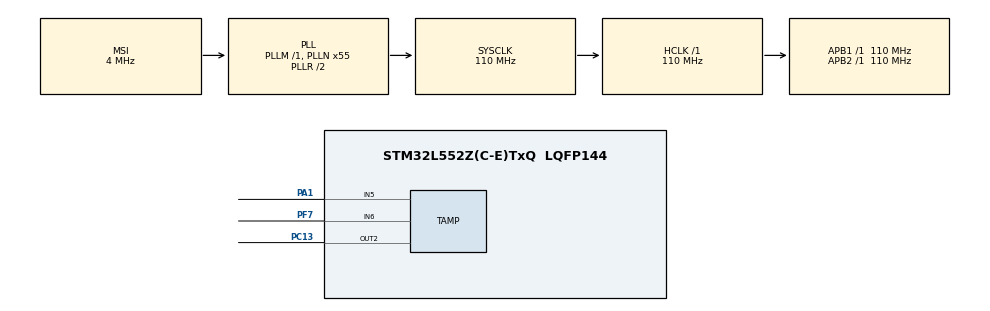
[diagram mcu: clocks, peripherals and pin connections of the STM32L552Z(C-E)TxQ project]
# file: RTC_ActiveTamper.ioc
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Mcu.Family=STM32L5
Mcu.Name=STM32L552Z(C-E)TxQ
Mcu.Package=LQFP144
NVIC.PriorityGroup=NVIC_PRIORITYGROUP_3
NVIC.TAMP_IRQn=true\:0\:0\:false\:false\:true\:true\:true\:true
PA1.Mode=Tamper_5_enabled
PA1.Signal=TAMP_IN5
PC13.Mode=Tamper 2 OUT enabled
PC13.Signal=TAMP_OUT2
PC14-OSC32_IN\ (PC14).Mode=LSE-External-Oscillator-for-RTC
PC14-OSC32_IN\ (PC14).Signal=RCC_OSC32_IN
PC15-OSC32_OUT\ (PC15).Mode=LSE-External-Oscillator-for-RTC
PC15-OSC32_OUT\ (PC15).Signal=RCC_OSC32_OUT
PF7.Mode=Tamper_6_enabled
PF7.Signal=TAMP_IN6
ProjectManager.HeapSize=0x200
ProjectManager.StackSize=0x400
ProjectManager.TargetToolchain=EWARM V8.32
RCC.AHBFreq_Value=110000000
RCC.APB1Freq_Value=110000000
RCC.APB1TimFreq_Value=110000000
RCC.APB2Freq_Value=110000000
RCC.APB2TimFreq_Value=110000000
RCC.CortexFreq_Value=110000000
RCC.HCLKFreq_Value=110000000
RCC.HSE_VALUE=16000000
RCC.HSI48_VALUE=48000000
RCC.HSI_VALUE=16000000
RCC.LSE_VALUE=32768
RCC.MSI_VALUE=4000000
RCC.PLLN=55
RCC.RTCClockSelection=RCC_RTCCLKSOURCE_LSE
RCC.SYSCLKFreq_VALUE=110000000
RCC.SYSCLKSource=RCC_SYSCLKSOURCE_PLLCLK
RCC.VCOOutputFreq_Value=220000000
TAMP.ActiveFilter=RTC_ATAMP_FILTER_ENABLE
TAMP.Interrupt5=RTC_ATAMP_INTERRUPT_ENABLE
TAMP.Interrupt6=RTC_ATAMP_INTERRUPT_ENABLE
VP_ICACHE_VS_ICACHE.Mode=DirectMappedCache
VP_PWR_VS_DBSignals.Mode=DisableDeadBatterySignals
VP_RTC_VS_RTC_Activate.Mode=RTC_Enabled
board=custom

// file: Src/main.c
/* USER CODE BEGIN Header */
/**
  ******************************************************************************
  * @file    RTC/RTC_ActiveTamper/Src/main.c
  * @author  MCD Application Team
  * @brief   This sample code shows how to use stm32l5xxxx RTC HAL API to
  *          program the Active Tampers.
  ******************************************************************************
  * @attention
  *
  * Copyright (c) 2020 STMicroelectronics.
  * All rights reserved.
  *
  * This software is licensed under terms that can be found in the LICENSE file
  * in the root directory of this software component.
  * If no LICENSE file comes with this software, it is provided AS-IS.
  *
  ******************************************************************************
  */
/* USER CODE END Header */
#include "main.h"

RTC_HandleTypeDef hrtc;

/* USER CODE BEGIN PV */
__IO FlagStatus TamperStatus;

/* USER CODE END PV */

void SystemClock_Config(void);
static void MX_GPIO_Init(void);
static void MX_ICACHE_Init(void);
static void MX_RTC_Init(void);
static void MX_TAMP_RTC_Init(void);

int main(void)
{
  /* USER CODE BEGIN 1 */
  uint32_t Seed[4] = {0xFEFEFEFEu, 0xAAAAAAAAu, 0x0u, 0xFFFF0000u};
  uint32_t i;
  /* USER CODE END 1 */

  /* MCU Configuration--------------------------------------------------------*/

  /* Reset of all peripherals, Initializes the Flash interface and the Systick. */
  HAL_Init();

  /* USER CODE BEGIN Init */
  /* Configure LED4 */
  BSP_LED_Init(LED4);

  /* USER CODE END Init */

  /* Configure the system clock */
  SystemClock_Config();

  /* Initialize all configured peripherals */
  MX_GPIO_Init();
  MX_ICACHE_Init();
  MX_RTC_Init();
  MX_TAMP_RTC_Init();
  /* USER CODE BEGIN 2 */

  /* Check if Tamper is not detected */
  for (i = 0; i < RTC_BKP_NUMBER; i++)
  {
    if (HAL_RTCEx_BKUPRead(&hrtc, i) == 0x0u)
    {
      /* Please verify that All Tampers In and the Tamper Out are linked together */
      Error_Handler();
    }
  }

  /* Update the seed with "random" values */
  for (i = 0; i < 5; i++)
  {
    Seed[0] -= 0xFEFEFEu * i;
    Seed[1] += 0xAAAu;
    Seed[2] += Seed[0] - Seed[1];
    Seed[3] += 4 * Seed[0] + 0x123456u;

    if (HAL_RTCEx_SetActiveSeed(&hrtc, Seed) != HAL_OK)
    {
      Error_Handler();
    }

    HAL_Delay(100);
  }

  /* Check if Tamper is not detected */
  for (i = 0; i < RTC_BKP_NUMBER; i++)
  {
    if (HAL_RTCEx_BKUPRead(&hrtc, i) == 0)
    {
       Error_Handler();
    }
  }
  /* Clear tamper interrupt flag */
  TamperStatus = RESET;

  /* Wait for tamper detection. User must disconnect the wire */
  while (TamperStatus == RESET);

  /* Disable Active Tampers */
  if (HAL_RTCEx_DeactivateActiveTampers(&hrtc) != HAL_OK)
  {
    Error_Handler();
  }

  /* Check that Backup registers have been cleared by the tamper detection */
  for (i = 0; i < RTC_BKP_NUMBER; i++)
  {
    if (HAL_RTCEx_BKUPRead(&hrtc, i) != 0)
    {
      Error_Handler();
    }
  }

  /* Test is OK Turn on LED4 */
  BSP_LED_On(LED4);

  /* USER CODE END 2 */

  /* Infinite loop */
  while (1)
  {

  }
}

void SystemClock_Config(void)
{
  RCC_OscInitTypeDef RCC_OscInitStruct = {0};
  RCC_ClkInitTypeDef RCC_ClkInitStruct = {0};

  /** Configure the main internal regulator output voltage
  */
  if (HAL_PWREx_ControlVoltageScaling(PWR_REGULATOR_VOLTAGE_SCALE0) != HAL_OK)
  {
    Error_Handler();
  }

  /** Configure LSE Drive Capability
  */
  HAL_PWR_EnableBkUpAccess();
  __HAL_RCC_LSEDRIVE_CONFIG(RCC_LSEDRIVE_LOW);

  /** Initializes the RCC Oscillators according to the specified parameters
  * in the RCC_OscInitTypeDef structure.
  */
  RCC_OscInitStruct.OscillatorType = RCC_OSCILLATORTYPE_LSE|RCC_OSCILLATORTYPE_MSI;
  RCC_OscInitStruct.LSEState = RCC_LSE_ON_RTC_ONLY;
  RCC_OscInitStruct.MSIState = RCC_MSI_ON;
  RCC_OscInitStruct.MSICalibrationValue = RCC_MSICALIBRATION_DEFAULT;
  RCC_OscInitStruct.MSIClockRange = RCC_MSIRANGE_6;
  RCC_OscInitStruct.PLL.PLLState = RCC_PLL_ON;
  RCC_OscInitStruct.PLL.PLLSource = RCC_PLLSOURCE_MSI;
  RCC_OscInitStruct.PLL.PLLM = 1;
  RCC_OscInitStruct.PLL.PLLN = 55;
  RCC_OscInitStruct.PLL.PLLP = RCC_PLLP_DIV7;
  RCC_OscInitStruct.PLL.PLLQ = RCC_PLLQ_DIV2;
  RCC_OscInitStruct.PLL.PLLR = RCC_PLLR_DIV2;
  if (HAL_RCC_OscConfig(&RCC_OscInitStruct) != HAL_OK)
  {
    Error_Handler();
  }

  /** Initializes the CPU, AHB and APB buses clocks
  */
  RCC_ClkInitStruct.ClockType = RCC_CLOCKTYPE_HCLK|RCC_CLOCKTYPE_SYSCLK
                              |RCC_CLOCKTYPE_PCLK1|RCC_CLOCKTYPE_PCLK2;
  RCC_ClkInitStruct.SYSCLKSource = RCC_SYSCLKSOURCE_PLLCLK;
  RCC_ClkInitStruct.AHBCLKDivider = RCC_SYSCLK_DIV1;
  RCC_ClkInitStruct.APB1CLKDivider = RCC_HCLK_DIV1;
  RCC_ClkInitStruct.APB2CLKDivider = RCC_HCLK_DIV1;

  if (HAL_RCC_ClockConfig(&RCC_ClkInitStruct, FLASH_LATENCY_5) != HAL_OK)
  {
    Error_Handler();
  }
}

static void MX_ICACHE_Init(void)
{

  /** Enable instruction cache in 1-way (direct mapped cache)
  */
  if (HAL_ICACHE_ConfigAssociativityMode(ICACHE_1WAY) != HAL_OK)
  {
    Error_Handler();
  }
  if (HAL_ICACHE_Enable() != HAL_OK)
  {
    Error_Handler();
  }

}

static void MX_RTC_Init(void)
{

  RTC_PrivilegeStateTypeDef privilegeState = {0};

  /* USER CODE BEGIN RTC_Init 1 */

  /* Use __HAL_DBGMCU_FREEZE_RTC(); to freeze the RTC during debug */

  /* USER CODE END RTC_Init 1 */

  /** Initialize RTC Only
  */
  hrtc.Instance = RTC;
  hrtc.Init.HourFormat = RTC_HOURFORMAT_24;
  hrtc.Init.AsynchPrediv = 127;
  hrtc.Init.SynchPrediv = 255;
  hrtc.Init.OutPut = RTC_OUTPUT_DISABLE;
  hrtc.Init.OutPutRemap = RTC_OUTPUT_REMAP_NONE;
  hrtc.Init.OutPutPolarity = RTC_OUTPUT_POLARITY_HIGH;
  hrtc.Init.OutPutType = RTC_OUTPUT_TYPE_OPENDRAIN;
  hrtc.Init.OutPutPullUp = RTC_OUTPUT_PULLUP_NONE;
  if (HAL_RTC_Init(&hrtc) != HAL_OK)
  {
    Error_Handler();
  }
  privilegeState.rtcPrivilegeFull = RTC_PRIVILEGE_FULL_NO;
  privilegeState.backupRegisterPrivZone = RTC_PRIVILEGE_BKUP_ZONE_NONE;
  privilegeState.backupRegisterStartZone2 = RTC_BKP_DR0;
  privilegeState.backupRegisterStartZone3 = RTC_BKP_DR0;
  if (HAL_RTCEx_PrivilegeModeSet(&hrtc, &privilegeState) != HAL_OK)
  {
    Error_Handler();
  }
  /* USER CODE BEGIN RTC_Init 2 */

  /* Calendar ultra-low power mode */
  if (HAL_RTCEx_SetLowPowerCalib(&hrtc, RTC_LPCAL_SET) != HAL_OK)
  {
    Error_Handler();
  }

  /* Set all backup registers to 0xFFFFFFFF.
     Backup registers will be cleared by a tamper detection. */
  for (uint32_t i = 0; i < RTC_BKP_NUMBER; i++)
  {
    HAL_RTCEx_BKUPWrite(&hrtc, i, 0xFFFFFFFF);
  }
  /* USER CODE END RTC_Init 2 */

}

static void MX_TAMP_RTC_Init(void)
{

  RTC_ActiveTampersTypeDef sAllTamper = {0};

  /** Enable the RTC Active Tamper
  */
  sAllTamper.ActiveFilter = RTC_ATAMP_FILTER_ENABLE;
  sAllTamper.ActiveAsyncPrescaler = RTC_ATAMP_ASYNCPRES_RTCCLK;
  sAllTamper.TimeStampOnTamperDetection = RTC_TIMESTAMPONTAMPERDETECTION_ENABLE;
  sAllTamper.ActiveOutputChangePeriod = 0;
  sAllTamper.Seed[0] = 0x00000000;
  sAllTamper.Seed[1] = 0x00000000;
  sAllTamper.Seed[2] = 0x00000000;
  sAllTamper.Seed[3] = 0x00000000;
  sAllTamper.TampInput[RTC_ATAMP_5].Enable = RTC_ATAMP_ENABLE;
  sAllTamper.TampInput[RTC_ATAMP_5].Interrupt = RTC_ATAMP_INTERRUPT_ENABLE;
  sAllTamper.TampInput[RTC_ATAMP_5].Output = RTC_ATAMP_2;
  sAllTamper.TampInput[RTC_ATAMP_5].NoErase = RTC_TAMPER_ERASE_BACKUP_ENABLE;
  sAllTamper.TampInput[RTC_ATAMP_6].Enable = RTC_ATAMP_ENABLE;
  sAllTamper.TampInput[RTC_ATAMP_6].Interrupt = RTC_ATAMP_INTERRUPT_ENABLE;
  sAllTamper.TampInput[RTC_ATAMP_6].Output = RTC_ATAMP_2;
  sAllTamper.TampInput[RTC_ATAMP_6].NoErase = RTC_TAMPER_ERASE_BACKUP_ENABLE;
  if (HAL_RTCEx_SetActiveTampers(&hrtc, &sAllTamper) != HAL_OK)
  {
    Error_Handler();
  }

}

static void MX_GPIO_Init(void)
{

  /* GPIO Ports Clock Enable */
  __HAL_RCC_GPIOC_CLK_ENABLE();
  __HAL_RCC_GPIOF_CLK_ENABLE();
  __HAL_RCC_GPIOA_CLK_ENABLE();

}

/* USER CODE BEGIN 4 */
/**
  * @brief  Tamper event callback function
  * @param  RTC handle
  * @retval None
  */
void HAL_RTCEx_Tamper5EventCallback(RTC_HandleTypeDef *hrtc)
{
  TamperStatus = SET;
}

/* USER CODE END 4 */

void Error_Handler(void)
{
  /* USER CODE BEGIN Error_Handler_Debug */
  while (1)
  {
    BSP_LED_Toggle(LED4);
    HAL_Delay(100);
  }
  /* USER CODE END Error_Handler_Debug */
}
